VERSION ""

NS_ :

BS_:

BU_:

BO_ 1792 CCU_Ready: 1 Vector__XXX
 SG_ CCU_Ready : 0|1@1- (1,0) [0|0] "" Vector__XXX

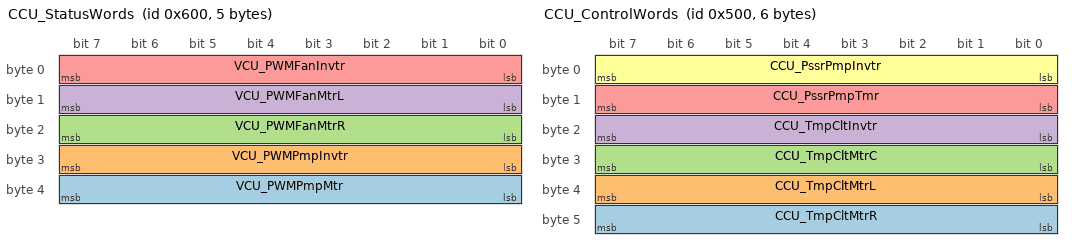
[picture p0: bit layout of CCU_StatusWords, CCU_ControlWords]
BO_ 1536 CCU_StatusWords: 5 Vector__XXX
 SG_ VCU_PWMPmpMtr : 32|8@1- (1,0) [0|0] "" Vector__XXX
 SG_ VCU_PWMPmpInvtr : 24|8@1- (1,0) [0|0] "" Vector__XXX
 SG_ VCU_PWMFanMtrR : 16|8@1- (1,0) [0|0] "" Vector__XXX
 SG_ VCU_PWMFanMtrL : 8|8@1- (1,0) [0|0] "" Vector__XXX
 SG_ VCU_PWMFanInvtr : 0|8@1- (1,0) [0|0] "" Vector__XXX

BO_ 1280 CCU_ControlWords: 6 Vector__XXX
 SG_ CCU_TmpCltMtrR : 40|8@1- (1,0) [0|0] "" Vector__XXX
 SG_ CCU_TmpCltMtrL : 32|8@1- (1,0) [0|0] "" Vector__XXX
 SG_ CCU_TmpCltMtrC : 24|8@1- (1,0) [0|0] "" Vector__XXX
 SG_ CCU_TmpCltInvtr : 16|8@1- (1,0) [0|0] "" Vector__XXX
 SG_ CCU_PssrPmpTmr : 8|8@1- (1,0) [0|0] "" Vector__XXX
 SG_ CCU_PssrPmpInvtr : 0|8@1- (1,0) [0|0] "PSI" Vector__XXX

CM_ SG_ 1536 VCU_PWMPmpMtr "Voltage or %";
CM_ SG_ 1536 VCU_PWMPmpInvtr "Voltage or %";
CM_ SG_ 1536 VCU_PWMFanMtrR "Voltage or %";
CM_ SG_ 1536 VCU_PWMFanMtrL "Voltage or %";
CM_ SG_ 1536 VCU_PWMFanInvtr "Voltage or %";
CM_ SG_ 1280 CCU_TmpCltMtrR "Does not exist";
CM_ SG_ 1280 CCU_TmpCltMtrL "Does not exist";
CM_ SG_ 1280 CCU_TmpCltMtrC "Temperature Sensor for Motor Loop Centre";
CM_ SG_ 1280 CCU_TmpCltInvtr "Temperature Sensor for Inverter Loop";
CM_ SG_ 1280 CCU_PssrPmpTmr "Pressure Sensor for Motor Loop";
CM_ SG_ 1280 CCU_PssrPmpInvtr "Pressure Sensor for Inverter Loop";
